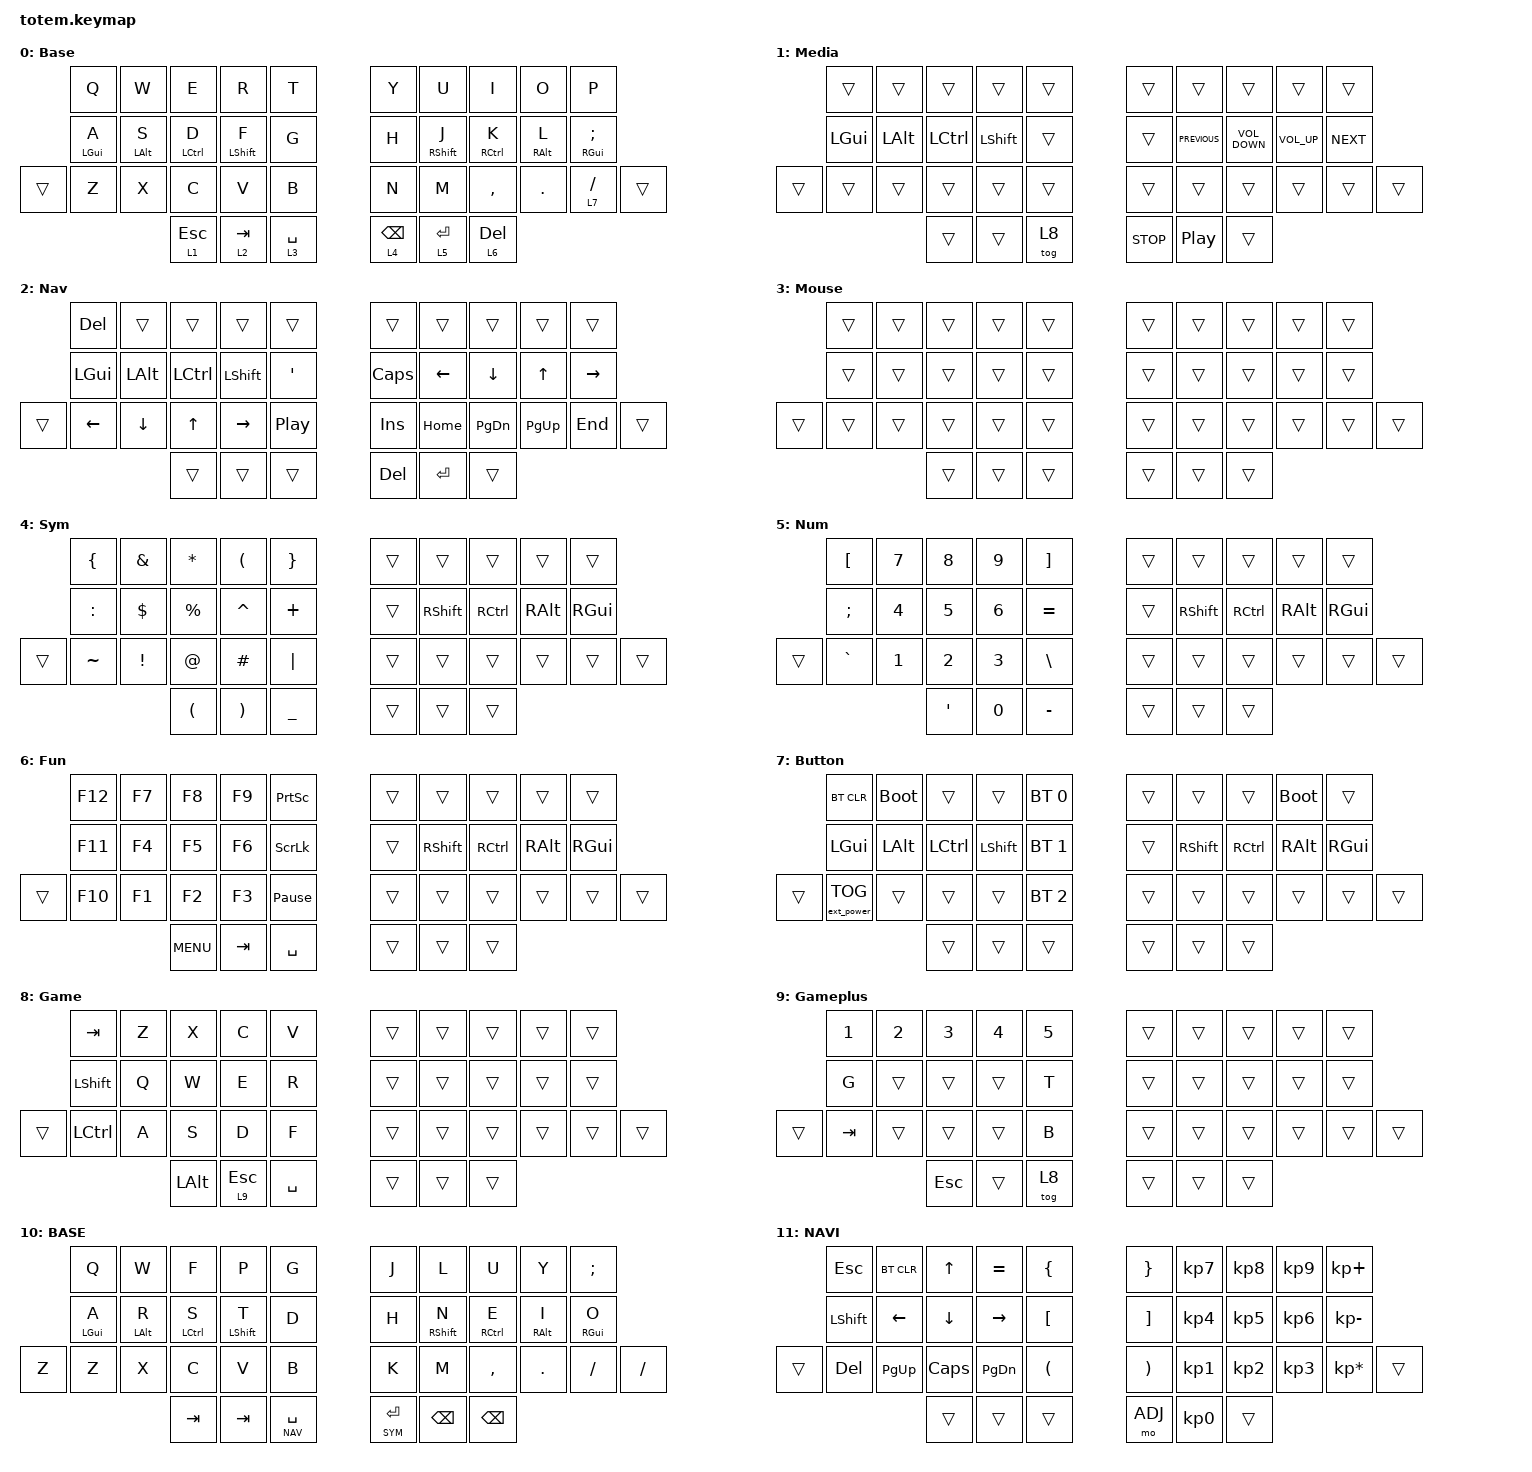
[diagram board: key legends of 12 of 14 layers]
//
//                                                        ▀▀▀▀▀     ▀▀▀▀▀          ▀▀█▀▀
//                                                        ▄▀▀▀▄  ▄  ▄▀▀▀▄  ▄  ▄▀▀▀▄  █  ▄▀▀▀▄
//                                                        █   █  █  █   █  █  █   █  █  █   █
//                                                         ▀▀▀   █   ▀▀▀   █   ▀▀▀   ▀   ▀▀▀
//                                                               █      ▄▄▄█▄▄▄    █   █  
//                                                               ▀      █  █  █     █▄█
//                                                             ▀▀▀▀▀    █  █  █      ▀
//                                                                      ▀  ▀  ▀
//
// ▄▄▄▄▄▄▄▄▄▄▄▄▄▄▄▄▄▄▄▄▄▄▄▄▄▄▄▄▄▄▄▄▄▄▄▄▄▄▄▄▄▄▄▄▄▄▄▄▄▄▄▄▄▄▄▄▄▄▄▄▄▄▄▄▄▄▄▄▄▄▄▄▄▄▄▄▄▄▄▄▄▄▄▄▄▄▄▄▄▄▄▄▄▄▄▄▄▄▄▄▄▄▄▄▄▄▄▄▄▄▄▄▄▄▄▄▄▄▄▄▄▄▄▄▄▄▄▄▄▄▄▄▄▄▄▄▄▄▄▄▄▄▄▄▄▄▄▄▄
       

#include <behaviors.dtsi>
#include <dt-bindings/zmk/keys.h>
#include <dt-bindings/zmk/bt.h>
#include <dt-bindings/zmk/outputs.h>
#include <dt-bindings/zmk/ext_power.h>

#define Base        0
#define Media       1
#define Nav         2
#define Mouse       3
#define Sym         4
#define Num         5
#define Fun         6
#define Button      7
#define Game        8
#define Gameplus    9

&mt {
    quick-tap-ms = <100>;
    global-quick-tap;
    flavor = "tap-preferred";
    tapping-term-ms = <170>;
};

&lt {
    tapping-term-ms = <240>;
    flavor = "balanced";
    quick-tap-ms = <150>;
};

/ {

    behaviors {
        hm: homerow_mods {
            compatible = "zmk,behavior-hold-tap";
            label = "HOMEROW_MODS";
            #binding-cells = <2>;
            flavor = "tap-preferred";
            tapping-term-ms = <240>;
            quick-tap-ms = <150>;
            global-quick-tap;
            bindings =
                <&kp>,
                <&kp>;
        };
    };

    keymap {
        compatible = "zmk,keymap";

    Base {
        label = "Base";
        bindings = <
                &kp Q       &kp W       &kp E         &kp R         &kp T                         &kp Y        &kp U         &kp I       &kp O               &kp P               
                &hm LGUI A  &hm LALT S  &hm LCTRL D   &hm LSHIFT F  &kp G                         &kp H  &hm RSHFT J   &hm RCTRL K  &hm RALT L  &hm RGUI SEMICOLON  
        &trans  &kp Z       &kp X       &kp C         &kp V         &kp B                         &kp N        &kp M     &kp COMMA     &kp DOT         &lt 7 SLASH  &trans
                                        &lt 1 ESCAPE  &lt 2 TAB     &lt 3 SPACE         &lt 4 BACKSPACE  &lt 5 ENTER  &lt 6 DELETE
        >;
    };

    Media {
        label = "Media";
        bindings = <
                &trans    &trans    &trans     &trans      &trans               &trans            &trans             &trans           &trans      &trans  
                &kp LGUI  &kp LALT  &kp LCTRL  &kp LSHIFT  &trans               &trans    &kp C_PREVIOUS  &kp C_VOLUME_DOWN  &kp C_VOLUME_UP  &kp C_NEXT  
        &trans  &trans    &trans    &trans     &trans      &trans               &trans            &trans             &trans           &trans      &trans  &trans
                                    &trans     &trans      &tog 8           &kp C_STOP  &kp C_PLAY_PAUSE             &trans  
        >;
    };

    Nav {
        label = "Nav";
        bindings = <
                &kp DELETE    &trans    &trans     &trans      &trans                       &trans     &trans         &trans       &trans       &trans  
                &kp LEFT_GUI  &kp LALT  &kp LCTRL  &kp LSHIFT  &kp SQT                    &kp CAPS   &kp LEFT       &kp DOWN       &kp UP    &kp RIGHT  
        &trans  &kp LEFT      &kp DOWN  &kp UP     &kp RIGHT   &kp C_PLAY_PAUSE         &kp INSERT   &kp HOME  &kp PAGE_DOWN  &kp PAGE_UP      &kp END  &trans
                                        &trans     &trans      &trans                   &kp DELETE  &kp ENTER         &trans
        >;
    };

    Mouse {
        label = "Mouse";
        bindings = <
                &trans  &trans  &trans  &trans  &trans          &trans  &trans  &trans  &trans  &trans  
                &trans  &trans  &trans  &trans  &trans          &trans  &trans  &trans  &trans  &trans  
        &trans  &trans  &trans  &trans  &trans  &trans          &trans  &trans  &trans  &trans  &trans  &trans
                                &trans  &trans  &trans          &trans  &trans  &trans
        >;
    };

    Sym {
        label = "Sym";
        bindings = <
                &kp LEFT_BRACE  &kp AMPERSAND  &kp ASTERISK         &kp LEFT_PARENTHESIS   &kp RIGHT_BRACE       &trans      &trans     &trans    &trans    &trans  
                &kp COLON       &kp DOLLAR     &kp PERCENT          &kp CARET              &kp PLUS              &trans  &kp RSHIFT  &kp RCTRL  &kp RALT  &kp RGUI  
        &trans  &kp TILDE       &kp EXCL       &kp AT               &kp HASH               &kp PIPE              &trans      &trans     &trans    &trans    &trans  &trans
                                              &kp LEFT_PARENTHESIS  &kp RIGHT_PARENTHESIS  &kp UNDERSCORE        &trans      &trans     &trans   
        >;
    };

    Num {
        label = "Num";
        bindings = <
                &kp LEFT_BRACKET  &kp NUMBER_7  &kp NUMBER_8  &kp NUMBER_9  &kp RIGHT_BRACKET       &trans      &trans     &trans    &trans    &trans  
                &kp SEMICOLON     &kp NUMBER_4  &kp NUMBER_5  &kp NUMBER_6  &kp EQUAL               &trans  &kp RSHIFT  &kp RCTRL  &kp RALT  &kp RGUI  
        &trans  &kp GRAVE         &kp NUMBER_1  &kp NUMBER_2  &kp NUMBER_3  &kp BACKSLASH           &trans      &trans     &trans    &trans    &trans  &trans
                                                &kp SQT       &kp NUMBER_0  &kp MINUS               &trans      &trans     &trans
        >;
    };

    Fun {
        label = "Fun";
        bindings = <
                &kp F12     &kp F7   &kp F8      &kp F9   &kp PRINTSCREEN          &trans      &trans     &trans    &trans    &trans  
                &kp F11     &kp F4   &kp F5      &kp F6   &kp SCROLLLOCK           &trans  &kp RSHIFT  &kp RCTRL  &kp RALT  &kp RGUI  
        &trans  &kp F10     &kp F1   &kp F2      &kp F3   &kp PAUSE_BREAK          &trans      &trans     &trans    &trans    &trans  &trans
                                     &kp C_MENU  &kp TAB  &kp SPACE                &trans      &trans     &trans
        >;
    };

    Button {
        label = "Button";
        bindings = <
                &bt BT_CLR         &bootloader  &trans     &trans      &bt BT_SEL 0         &trans      &trans     &trans  &bootloader    &trans  
                &kp LGUI           &kp LALT     &kp LCTRL  &kp LSHIFT  &bt BT_SEL 1         &trans  &kp RSHIFT  &kp RCTRL     &kp RALT  &kp RGUI  
        &trans  &ext_power EP_TOG  &trans       &trans     &trans      &bt BT_SEL 2         &trans      &trans     &trans       &trans    &trans  &trans
                                                &trans     &trans      &trans               &trans      &trans     &trans
        >;
    };

    Game {
        label = "Game";
        bindings = <
                &kp TAB         &kp Z  &kp X       &kp C         &kp V            &trans  &trans  &trans  &trans  &trans  
                &kp LEFT_SHIFT  &kp Q  &kp W       &kp E         &kp R            &trans  &trans  &trans  &trans  &trans  
        &trans  &kp LCTRL       &kp A  &kp S       &kp D         &kp F            &trans  &trans  &trans  &trans  &trans  &trans
                                       &kp LALT    &lt 9 ESCAPE  &kp SPACE        &trans  &trans  &trans
        >;
    };

    Gameplus {
        label = "Gameplus";
        bindings = <
                &kp NUMBER_1  &kp NUMBER_2  &kp NUMBER_3  &kp NUMBER_4  &kp NUMBER_5        &trans  &trans  &trans  &trans  &trans  
                &kp G         &trans        &trans        &trans        &kp T               &trans  &trans  &trans  &trans  &trans  
        &trans  &kp TAB       &trans        &trans        &trans        &kp B               &trans  &trans  &trans  &trans  &trans  &trans
                                            &kp ESCAPE    &trans        &tog 8              &trans  &trans  &trans
        >;
    };
  };

#define BASE 0
#define NAV  1
#define SYM  2
#define ADJ  3

&mt {
  quick-tap-ms = <100>;
  global-quick-tap;
  flavor = "tap-preferred";
  tapping-term-ms = <170>;
};

/ {
    combos {
            compatible = "zmk,combos";
            combo_esc {
                timeout-ms = <50>;
                key-positions = <0 1>;
                bindings = <&kp ESC>;
            };
    };

    macros {
        gif: gif {
            label = "giphy";
            compatible = "zmk,behavior-macro";
            #binding-cells = <0>;
            bindings
                = <&macro_press &kp LSHFT>
                , <&macro_tap &kp N2>
                , <&macro_release &kp LSHFT>
                , <&macro_tap &kp G &kp I &kp F>
                ;
        };
    };

        keymap {
                compatible = "zmk,keymap";
// ▄▄▄▄▄▄▄▄▄▄▄▄▄▄▄▄▄▄▄▄▄▄▄▄▄▄▄▄▄▄▄▄▄▄▄▄▄▄▄▄▄▄▄▄▄▄▄▄▄▄▄▄▄▄▄▄▄▄▄▄▄▄▄▄▄▄▄▄▄▄▄▄▄▄▄▄▄▄▄▄▄▄▄▄▄▄▄▄▄▄▄▄▄▄▄▄▄▄▄▄▄▄▄▄▄▄▄▄▄▄▄▄▄▄▄▄▄▄▄▄▄▄▄▄▄▄▄▄▄▄▄▄▄▄▄▄▄▄▄▄▄▄▄▄▄▄▄▄▄

                base_layer {
// ┏━━━━━━━━━━━━━━━━━━━━━━━━━━━━━━━━━━━━━━━┓
label= "BASE"                              ;
// ┗━━━━━━━━━━━━━━━━━━━━━━━━━━━━━━━━━━━━━━━┛
//             ┏━━━━━━━━━━━┳━━━━━━━━━━━┳━━━━━━━━━━━┳━━━━━━━━━━━┳━━━━━━━━━━━┓   ┏━━━━━━━━━━━┳━━━━━━━━━━━┳━━━━━━━━━━━┳━━━━━━━━━━━┳━━━━━━━━━━━┓
//             ┃     Q     ┃     W     ┃     F     ┃     P     ┃     G     ┃   ┃     J     ┃     L     ┃     U     ┃     Y     ┃     ;     ┃
//             ┣━━━━━━━━━━━╋━━━━━━━━━━━╋━━━━━━━━━━━╋━━━━━━━━━━━╋━━━━━━━━━━━┫   ┣━━━━━━━━━━━╋━━━━━━━━━━━╋━━━━━━━━━━━╋━━━━━━━━━━━╋━━━━━━━━━━━┫
//             ┃     A     ┃     R     ┃     S     ┃     T     ┃     D     ┃   ┃     H     ┃     N     ┃     E     ┃     I     ┃     O     ┃
// ┏━━━━━━━━━━━╋━━━━━━━━━━━╋━━━━━━━━━━━╋━━━━━━━━━━━╋━━━━━━━━━━━╋━━━━━━━━━━━┫   ┣━━━━━━━━━━━╋━━━━━━━━━━━╋━━━━━━━━━━━╋━━━━━━━━━━━╋━━━━━━━━━━━╋━━━━━━━━━━━┓
// ┃           ┃     Z     ┃     X     ┃     C     ┃     V     ┃     B     ┃   ┃     K     ┃     M     ┃     ,     ┃     .     ┃     /     ┃           ┃
// ┗━━━━━━━━━━━┻━━━━━━━━━━━┻━━━━━━━━━━━╋━━━━━━━━━━━╋━━━━━━━━━━━╋━━━━━━━━━━━┫   ┣━━━━━━━━━━━╋━━━━━━━━━━━╋━━━━━━━━━━━╋━━━━━━━━━━━┻━━━━━━━━━━━┻━━━━━━━━━━━┛
//                                     ┃           ┃    TAB    ┃    SPC    ┃   ┃   ENTER   ┃   BSPC    ┃           ┃
//                                     ┗━━━━━━━━━━━┻━━━━━━━━━━━┻━━━━━━━━━━━┛   ┗━━━━━━━━━━━┻━━━━━━━━━━━┻━━━━━━━━━━━┛
 bindings = <
// ╷           ╷           ╷           ╷           ╷           ╷           ╷   ╷           ╷           ╷           ╷           ╷           ╷           ╷

                &kp Q       &kp W       &kp F       &kp P       &kp G           &kp J       &kp L       &kp U       &kp Y       &kp SEMI
                &mt LGUI A  &mt LALT R  &mt LCTRL S &mt LSHFT T &kp D           &kp H       &mt RSHFT N &mt RCTRL E &mt RALT I  &mt RGUI O
    &kp Z       &kp Z       &kp X       &kp C       &kp V       &kp B           &kp K       &kp M       &kp COMMA   &kp DOT     &kp FSLH    &kp FSLH
                                        &kp TAB     &kp TAB     &lt NAV SPACE   &lt SYM RET &kp BSPC    &kp BSPC
                        >;
                };

// ▄▄▄▄▄▄▄▄▄▄▄▄▄▄▄▄▄▄▄▄▄▄▄▄▄▄▄▄▄▄▄▄▄▄▄▄▄▄▄▄▄▄▄▄▄▄▄▄▄▄▄▄▄▄▄▄▄▄▄▄▄▄▄▄▄▄▄▄▄▄▄▄▄▄▄▄▄▄▄▄▄▄▄▄▄▄▄▄▄▄▄▄▄▄▄▄▄▄▄▄▄▄▄▄▄▄▄▄▄▄▄▄▄▄▄▄▄▄▄▄▄▄▄▄▄▄▄▄▄▄▄▄▄▄▄▄▄▄▄▄▄▄▄▄▄▄▄▄▄


                nav_layer {
// ┏━━━━━━━━━━━━━━━━━━━━━━━━━━━━━━━━━━━━━━━┓
label= "NAVI"                              ;
// ┗━━━━━━━━━━━━━━━━━━━━━━━━━━━━━━━━━━━━━━━┛
//             ┏━━━━━━━━━━━┳━━━━━━━━━━━┳━━━━━━━━━━━┳━━━━━━━━━━━┳━━━━━━━━━━━┓   ┏━━━━━━━━━━━┳━━━━━━━━━━━┳━━━━━━━━━━━┳━━━━━━━━━━━┳━━━━━━━━━━━┓
//             ┃           ┃           ┃     UP    ┃           ┃     {     ┃   ┃     }     ┃     7     ┃     8     ┃     9     ┃     +     ┃
//             ┣━━━━━━━━━━━╋━━━━━━━━━━━╋━━━━━━━━━━━╋━━━━━━━━━━━╋━━━━━━━━━━━┫   ┣━━━━━━━━━━━╋━━━━━━━━━━━╋━━━━━━━━━━━╋━━━━━━━━━━━╋━━━━━━━━━━━┫
//             ┃   SHIFT   ┃   LEFT    ┃    DOWN   ┃   RIGHT   ┃     [     ┃   ┃     ]     ┃     4     ┃     5     ┃     6     ┃     -     ┃
// ┏━━━━━━━━━━━╋━━━━━━━━━━━╋━━━━━━━━━━━╋━━━━━━━━━━━╋━━━━━━━━━━━╋━━━━━━━━━━━┫   ┣━━━━━━━━━━━╋━━━━━━━━━━━╋━━━━━━━━━━━╋━━━━━━━━━━━╋━━━━━━━━━━━╋━━━━━━━━━━━┓
// ┃           ┃           ┃   P UP    ┃  C LOCK   ┃  P DOWN   ┃     (     ┃   ┃     )     ┃     1     ┃     2     ┃     3     ┃     *     ┃           ┃
// ┗━━━━━━━━━━━┻━━━━━━━━━━━┻━━━━━━━━━━━╋━━━━━━━━━━━╋━━━━━━━━━━━╋━━━━━━━━━━━┫   ┣━━━━━━━━━━━╋━━━━━━━━━━━╋━━━━━━━━━━━╋━━━━━━━━━━━┻━━━━━━━━━━━┻━━━━━━━━━━━┛
//                                     ┃           ┃    TAB    ┃    SPC    ┃   ┃    DEL    ┃     0     ┃           ┃
//                                     ┗━━━━━━━━━━━┻━━━━━━━━━━━┻━━━━━━━━━━━┛   ┗━━━━━━━━━━━┻━━━━━━━━━━━┻━━━━━━━━━━━┛
 bindings = <
// ╷           ╷           ╷           ╷           ╷           ╷           ╷   ╷           ╷           ╷           ╷           ╷           ╷           ╷

                &kp ESC     &bt BT_CLR  &kp UP      &kp EQUAL   &kp LBRC        &kp RBRC    &kp KP_N7   &kp KP_N8   &kp KP_N9   &kp KP_PLUS
                &kp LSHFT   &kp LEFT    &kp DOWN    &kp RIGHT   &kp LBKT        &kp RBKT    &kp KP_N4   &kp KP_N5   &kp KP_N6   &kp KP_MINUS
    &trans      &kp DEL     &kp PG_UP   &kp CAPS    &kp PG_DN   &kp LPAR        &kp RPAR    &kp KP_N1   &kp KP_N2   &kp KP_N3   &kp KP_MULTIPLY &trans      
                                        &trans      &trans      &trans          &mo ADJ     &kp KP_N0   &trans      
                        >;
                };

// ▄▄▄▄▄▄▄▄▄▄▄▄▄▄▄▄▄▄▄▄▄▄▄▄▄▄▄▄▄▄▄▄▄▄▄▄▄▄▄▄▄▄▄▄▄▄▄▄▄▄▄▄▄▄▄▄▄▄▄▄▄▄▄▄▄▄▄▄▄▄▄▄▄▄▄▄▄▄▄▄▄▄▄▄▄▄▄▄▄▄▄▄▄▄▄▄▄▄▄▄▄▄▄▄▄▄▄▄▄▄▄▄▄▄▄▄▄▄▄▄▄▄▄▄▄▄▄▄▄▄▄▄▄▄▄▄▄▄▄▄▄▄▄▄▄▄▄▄▄


                sim_layer {
// ┏━━━━━━━━━━━━━━━━━━━━━━━━━━━━━━━━━━━━━━━┓
label= "SYM"                               ;
// ┗━━━━━━━━━━━━━━━━━━━━━━━━━━━━━━━━━━━━━━━┛
//             ┏━━━━━━━━━━━┳━━━━━━━━━━━┳━━━━━━━━━━━┳━━━━━━━━━━━┳━━━━━━━━━━━┓   ┏━━━━━━━━━━━┳━━━━━━━━━━━┳━━━━━━━━━━━┳━━━━━━━━━━━┳━━━━━━━━━━━┓
//             ┃     !     ┃     @     ┃     #     ┃     $     ┃     %     ┃   ┃     ˆ     ┃     &     ┃     Ü     ┃     '     ┃     "     ┃
//             ┣━━━━━━━━━━━╋━━━━━━━━━━━╋━━━━━━━━━━━╋━━━━━━━━━━━╋━━━━━━━━━━━┫   ┣━━━━━━━━━━━╋━━━━━━━━━━━╋━━━━━━━━━━━╋━━━━━━━━━━━╋━━━━━━━━━━━┫
//             ┃     Ä     ┃           ┃    SZ     ┃           ┃           ┃   ┃   MUTE    ┃   YEN     ┃   EURO    ┃  POUND    ┃     Ö     ┃
// ┏━━━━━━━━━━━╋━━━━━━━━━━━╋━━━━━━━━━━━╋━━━━━━━━━━━╋━━━━━━━━━━━╋━━━━━━━━━━━┫   ┣━━━━━━━━━━━╋━━━━━━━━━━━╋━━━━━━━━━━━╋━━━━━━━━━━━╋━━━━━━━━━━━╋━━━━━━━━━━━┓
// ┃           ┃  EMAIL1   ┃  EMAIL2   ┃           ┃           ┃           ┃   ┃   VOL-    ┃   VOL+    ┃   LAST    ┃   NEXT    ┃     \     ┃           ┃
// ┗━━━━━━━━━━━┻━━━━━━━━━━━┻━━━━━━━━━━━╋━━━━━━━━━━━╋━━━━━━━━━━━╋━━━━━━━━━━━┫   ┣━━━━━━━━━━━╋━━━━━━━━━━━╋━━━━━━━━━━━╋━━━━━━━━━━━┻━━━━━━━━━━━┻━━━━━━━━━━━┛
//                                     ┃           ┃    GIF    ┃    ADJ    ┃   ┃           ┃           ┃           ┃
//                                     ┗━━━━━━━━━━━┻━━━━━━━━━━━┻━━━━━━━━━━━┛   ┗━━━━━━━━━━━┻━━━━━━━━━━━┻━━━━━━━━━━━┛
 bindings = <
// ╷           ╷           ╷           ╷           ╷           ╷           ╷   ╷           ╷           ╷           ╷           ╷           ╷           ╷

                &kp EXCL    &kp AT      &kp HASH    &kp DLLR    &kp PRCNT       &kp CARET   &kp AMPS    &kp RA(U)   &kp SQT     &kp DQT       
                &kp RA(A)   &trans      &kp RA(S)   &trans      &trans          &kp C_MUTE  &kp LS(RA(N4)) &kp RA(N5) &kp RA(N4)   &kp RA(O) 
    &trans      &kp RA(F18) &kp RA(F19) &trans      &trans      &trans          &kp C_VOL_DN &kp C_VOL_UP &kp C_PREV &kp C_NEXT  &kp BSLH   &trans         
                                        &trans      &gif        &mo ADJ         &trans      &kp C_PP    &trans      
                        >;
                };

// ▄▄▄▄▄▄▄▄▄▄▄▄▄▄▄▄▄▄▄▄▄▄▄▄▄▄▄▄▄▄▄▄▄▄▄▄▄▄▄▄▄▄▄▄▄▄▄▄▄▄▄▄▄▄▄▄▄▄▄▄▄▄▄▄▄▄▄▄▄▄▄▄▄▄▄▄▄▄▄▄▄▄▄▄▄▄▄▄▄▄▄▄▄▄▄▄▄▄▄▄▄▄▄▄▄▄▄▄▄▄▄▄▄▄▄▄▄▄▄▄▄▄▄▄▄▄▄▄▄▄▄▄▄▄▄▄▄▄▄▄▄▄▄▄▄▄▄▄▄


                adjust_layer {
// ┏━━━━━━━━━━━━━━━━━━━━━━━━━━━━━━━━━━━━━━━┓
label= "ADJ"                               ;
// ┗━━━━━━━━━━━━━━━━━━━━━━━━━━━━━━━━━━━━━━━┛
//             ┏━━━━━━━━━━━┳━━━━━━━━━━━┳━━━━━━━━━━━┳━━━━━━━━━━━┳━━━━━━━━━━━┓   ┏━━━━━━━━━━━┳━━━━━━━━━━━┳━━━━━━━━━━━┳━━━━━━━━━━━┳━━━━━━━━━━━┓
//             ┃   RESET   ┃ BT CLEAR  ┃  OUT TOG  ┃           ┃           ┃   ┃           ┃    F7     ┃    F8     ┃    F9     ┃    F12    ┃
//             ┣━━━━━━━━━━━╋━━━━━━━━━━━╋━━━━━━━━━━━╋━━━━━━━━━━━╋━━━━━━━━━━━┫   ┣━━━━━━━━━━━╋━━━━━━━━━━━╋━━━━━━━━━━━╋━━━━━━━━━━━╋━━━━━━━━━━━┫
//             ┃ BOOTLOAD  ┃ BT NEXT   ┃           ┃           ┃           ┃   ┃           ┃    F4     ┃    F5     ┃    F6     ┃    F11    ┃
// ┏━━━━━━━━━━━╋━━━━━━━━━━━╋━━━━━━━━━━━╋━━━━━━━━━━━╋━━━━━━━━━━━╋━━━━━━━━━━━┫   ┣━━━━━━━━━━━╋━━━━━━━━━━━╋━━━━━━━━━━━╋━━━━━━━━━━━╋━━━━━━━━━━━╋━━━━━━━━━━━┓
// ┃           ┃           ┃ BT PREV   ┃           ┃           ┃           ┃   ┃           ┃    F1     ┃    F2     ┃    F3     ┃    F10    ┃           ┃
// ┗━━━━━━━━━━━┻━━━━━━━━━━━┻━━━━━━━━━━━╋━━━━━━━━━━━╋━━━━━━━━━━━╋━━━━━━━━━━━┫   ┣━━━━━━━━━━━╋━━━━━━━━━━━╋━━━━━━━━━━━╋━━━━━━━━━━━┻━━━━━━━━━━━┻━━━━━━━━━━━┛
//                                     ┃           ┃           ┃           ┃   ┃           ┃           ┃           ┃
//                                     ┗━━━━━━━━━━━┻━━━━━━━━━━━┻━━━━━━━━━━━┛   ┗━━━━━━━━━━━┻━━━━━━━━━━━┻━━━━━━━━━━━┛
 bindings = <
// ╷           ╷           ╷           ╷           ╷           ╷           ╷   ╷           ╷           ╷           ╷           ╷           ╷           ╷

                &sys_reset  &bt BT_CLR &out OUT_TOG &trans      &trans          &trans      &kp F7      &kp F8      &kp F9      &kp F12
                &bootloader &bt BT_NXT  &trans      &trans      &trans          &trans      &kp F4      &kp F5      &kp F6      &kp F11  
    &trans      &trans      &bt BT_PRV  &trans      &trans      &trans          &trans      &kp F1      &kp F2      &kp F3      &kp F10     &trans         
                                        &trans      &trans      &trans          &trans      &trans      &trans      
                        >;
                };
        };
};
